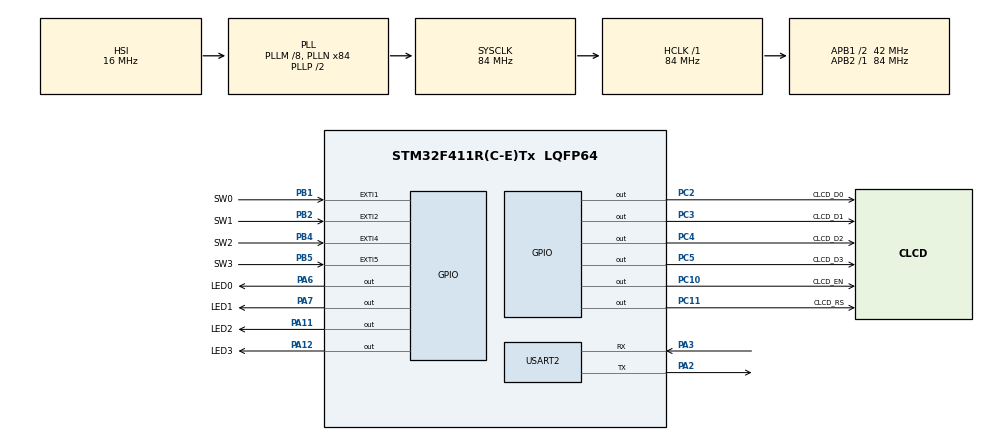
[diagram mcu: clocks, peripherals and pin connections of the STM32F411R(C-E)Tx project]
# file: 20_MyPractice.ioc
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Mcu.Family=STM32F4
Mcu.Name=STM32F411R(C-E)Tx
Mcu.Package=LQFP64
NVIC.EXTI1_IRQn=true\:0\:0\:false\:false\:true\:true\:true\:true
NVIC.EXTI2_IRQn=true\:0\:0\:false\:false\:true\:true\:true\:true
NVIC.EXTI4_IRQn=true\:0\:0\:false\:false\:true\:true\:true\:true
NVIC.EXTI9_5_IRQn=true\:0\:0\:false\:false\:true\:true\:true\:true
NVIC.PriorityGroup=NVIC_PRIORITYGROUP_4
PA11.GPIO_Label=LED2
PA11.Signal=GPIO_Output
PA12.GPIO_Label=LED3
PA12.Signal=GPIO_Output
PA13.Mode=Serial_Wire
PA13.Signal=SYS_JTMS-SWDIO
PA14.Mode=Serial_Wire
PA14.Signal=SYS_JTCK-SWCLK
PA2.Mode=Asynchronous
PA2.Signal=USART2_TX
PA3.Mode=Asynchronous
PA3.Signal=USART2_RX
PA6.GPIO_Label=LED0
PA6.Signal=GPIO_Output
PA7.GPIO_Label=LED1
PA7.Signal=GPIO_Output
PB1.GPIO_Label=SW0
PB1.GPIO_ModeDefaultEXTI=GPIO_MODE_IT_RISING
PB1.Signal=GPXTI1
PB2.GPIO_Label=SW1
PB2.Signal=GPXTI2
PB4.GPIO_Label=SW2
PB4.Signal=GPXTI4
PB5.GPIO_Label=SW3
PB5.Signal=GPXTI5
PC10.GPIO_Label=CLCD_EN
PC10.Signal=GPIO_Output
PC11.GPIO_Label=CLCD_RS
PC11.Signal=GPIO_Output
PC2.GPIO_Label=CLCD_D0
PC2.Signal=GPIO_Output
PC3.GPIO_Label=CLCD_D1
PC3.Signal=GPIO_Output
PC4.GPIO_Label=CLCD_D2
PC4.Signal=GPIO_Output
PC5.GPIO_Label=CLCD_D3
PC5.Signal=GPIO_Output
ProjectManager.HeapSize=0x200
ProjectManager.StackSize=0x400
ProjectManager.TargetToolchain=STM32CubeIDE
RCC.48MHZClocksFreq_Value=42000000
RCC.AHBFreq_Value=84000000
RCC.APB1CLKDivider=RCC_HCLK_DIV2
RCC.APB1Freq_Value=42000000
RCC.APB1TimFreq_Value=84000000
RCC.APB2Freq_Value=84000000
RCC.APB2TimFreq_Value=84000000
RCC.CortexFreq_Value=84000000
RCC.HCLKFreq_Value=84000000
RCC.HSE_VALUE=25000000
RCC.HSI_VALUE=16000000
RCC.LSE_VALUE=32768
RCC.PLLM=8
RCC.PLLN=84
RCC.SYSCLKFreq_VALUE=84000000
RCC.SYSCLKSource=RCC_SYSCLKSOURCE_PLLCLK
RCC.VCOOutputFreq_Value=168000000
USART2.VirtualMode=VM_ASYNC
board=custom

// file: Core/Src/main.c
/* USER CODE BEGIN Header */
/**
  ******************************************************************************
  * @file           : main.c
  * @brief          : Main program body
  ******************************************************************************
  * @attention
  *
  * Copyright (c) 2024 STMicroelectronics.
  * All rights reserved.
  *
  * This software is licensed under terms that can be found in the LICENSE file
  * in the root directory of this software component.
  * If no LICENSE file comes with this software, it is provided AS-IS.
  *
  ******************************************************************************
  */
/* USER CODE END Header */
#include "main.h"

/* USER CODE BEGIN Includes */
#include <stdio.h>
#include "clcd\clcd.h"
/* USER CODE END Includes */

UART_HandleTypeDef huart2;

void SystemClock_Config(void);
static void MX_GPIO_Init(void);
static void MX_USART2_UART_Init(void);

int main(void)
{

  /* MCU Configuration--------------------------------------------------------*/

  /* Reset of all peripherals, Initializes the Flash interface and the Systick. */
  HAL_Init();

  /* Configure the system clock */
  SystemClock_Config();

  /* Initialize all configured peripherals */
  MX_GPIO_Init();
  MX_USART2_UART_Init();
  /* USER CODE BEGIN 2 */
  CLCD_Init (16, 2);
  HAL_Delay (1000);
  /* USER CODE END 2 */

  /* Infinite loop */
  /* USER CODE BEGIN WHILE */
  CLCD_Clear ();
  char sBuf[16] = { 0 };
  char count = 0;
  while (1)
  {
      sprintf (sBuf, "Count Num = %3d", count);
      CLCD_Puts (0, 1, sBuf);

      if (count >= 100)
        count = 0;
      else
        count++;

      HAL_Delay (200);
    /* USER CODE END WHILE */

  }
}

void SystemClock_Config(void)
{
  RCC_OscInitTypeDef RCC_OscInitStruct = {0};
  RCC_ClkInitTypeDef RCC_ClkInitStruct = {0};

  /** Configure the main internal regulator output voltage
  */
  __HAL_RCC_PWR_CLK_ENABLE();
  __HAL_PWR_VOLTAGESCALING_CONFIG(PWR_REGULATOR_VOLTAGE_SCALE1);

  /** Initializes the RCC Oscillators according to the specified parameters
  * in the RCC_OscInitTypeDef structure.
  */
  RCC_OscInitStruct.OscillatorType = RCC_OSCILLATORTYPE_HSI;
  RCC_OscInitStruct.HSIState = RCC_HSI_ON;
  RCC_OscInitStruct.HSICalibrationValue = RCC_HSICALIBRATION_DEFAULT;
  RCC_OscInitStruct.PLL.PLLState = RCC_PLL_ON;
  RCC_OscInitStruct.PLL.PLLSource = RCC_PLLSOURCE_HSI;
  RCC_OscInitStruct.PLL.PLLM = 8;
  RCC_OscInitStruct.PLL.PLLN = 84;
  RCC_OscInitStruct.PLL.PLLP = RCC_PLLP_DIV2;
  RCC_OscInitStruct.PLL.PLLQ = 4;
  if (HAL_RCC_OscConfig(&RCC_OscInitStruct) != HAL_OK)
  {
    Error_Handler();
  }

  /** Initializes the CPU, AHB and APB buses clocks
  */
  RCC_ClkInitStruct.ClockType = RCC_CLOCKTYPE_HCLK|RCC_CLOCKTYPE_SYSCLK
                              |RCC_CLOCKTYPE_PCLK1|RCC_CLOCKTYPE_PCLK2;
  RCC_ClkInitStruct.SYSCLKSource = RCC_SYSCLKSOURCE_PLLCLK;
  RCC_ClkInitStruct.AHBCLKDivider = RCC_SYSCLK_DIV1;
  RCC_ClkInitStruct.APB1CLKDivider = RCC_HCLK_DIV2;
  RCC_ClkInitStruct.APB2CLKDivider = RCC_HCLK_DIV1;

  if (HAL_RCC_ClockConfig(&RCC_ClkInitStruct, FLASH_LATENCY_2) != HAL_OK)
  {
    Error_Handler();
  }
}

static void MX_USART2_UART_Init(void)
{

  huart2.Instance = USART2;
  huart2.Init.BaudRate = 115200;
  huart2.Init.WordLength = UART_WORDLENGTH_8B;
  huart2.Init.StopBits = UART_STOPBITS_1;
  huart2.Init.Parity = UART_PARITY_NONE;
  huart2.Init.Mode = UART_MODE_TX_RX;
  huart2.Init.HwFlowCtl = UART_HWCONTROL_NONE;
  huart2.Init.OverSampling = UART_OVERSAMPLING_16;
  if (HAL_UART_Init(&huart2) != HAL_OK)
  {
    Error_Handler();
  }

}

static void MX_GPIO_Init(void)
{
  GPIO_InitTypeDef GPIO_InitStruct = {0};

  /* GPIO Ports Clock Enable */
  __HAL_RCC_GPIOC_CLK_ENABLE();
  __HAL_RCC_GPIOA_CLK_ENABLE();
  __HAL_RCC_GPIOB_CLK_ENABLE();

  /*Configure GPIO pin Output Level */
  HAL_GPIO_WritePin(GPIOC, CLCD_D0_Pin|CLCD_D1_Pin|CLCD_D2_Pin|CLCD_D3_Pin
                          |CLCD_EN_Pin|CLCD_RS_Pin, GPIO_PIN_RESET);

  /*Configure GPIO pin Output Level */
  HAL_GPIO_WritePin(GPIOA, LED0_Pin|LED1_Pin|LED2_Pin|LED3_Pin, GPIO_PIN_RESET);

  /*Configure GPIO pins : CLCD_D0_Pin CLCD_D1_Pin CLCD_D2_Pin CLCD_D3_Pin
                           CLCD_EN_Pin CLCD_RS_Pin */
  GPIO_InitStruct.Pin = CLCD_D0_Pin|CLCD_D1_Pin|CLCD_D2_Pin|CLCD_D3_Pin
                          |CLCD_EN_Pin|CLCD_RS_Pin;
  GPIO_InitStruct.Mode = GPIO_MODE_OUTPUT_PP;
  GPIO_InitStruct.Pull = GPIO_NOPULL;
  GPIO_InitStruct.Speed = GPIO_SPEED_FREQ_LOW;
  HAL_GPIO_Init(GPIOC, &GPIO_InitStruct);

  /*Configure GPIO pins : LED0_Pin LED1_Pin LED2_Pin LED3_Pin */
  GPIO_InitStruct.Pin = LED0_Pin|LED1_Pin|LED2_Pin|LED3_Pin;
  GPIO_InitStruct.Mode = GPIO_MODE_OUTPUT_PP;
  GPIO_InitStruct.Pull = GPIO_NOPULL;
  GPIO_InitStruct.Speed = GPIO_SPEED_FREQ_LOW;
  HAL_GPIO_Init(GPIOA, &GPIO_InitStruct);

  /*Configure GPIO pins : SW0_Pin SW1_Pin SW2_Pin SW3_Pin */
  GPIO_InitStruct.Pin = SW0_Pin|SW1_Pin|SW2_Pin|SW3_Pin;
  GPIO_InitStruct.Mode = GPIO_MODE_IT_RISING;
  GPIO_InitStruct.Pull = GPIO_NOPULL;
  HAL_GPIO_Init(GPIOB, &GPIO_InitStruct);

  /* EXTI interrupt init*/
  HAL_NVIC_SetPriority(EXTI1_IRQn, 0, 0);
  HAL_NVIC_EnableIRQ(EXTI1_IRQn);

  HAL_NVIC_SetPriority(EXTI2_IRQn, 0, 0);
  HAL_NVIC_EnableIRQ(EXTI2_IRQn);

  HAL_NVIC_SetPriority(EXTI4_IRQn, 0, 0);
  HAL_NVIC_EnableIRQ(EXTI4_IRQn);

  HAL_NVIC_SetPriority(EXTI9_5_IRQn, 0, 0);
  HAL_NVIC_EnableIRQ(EXTI9_5_IRQn);

}

void Error_Handler(void)
{
  __disable_irq();
  while (1)
  {
  }
}
